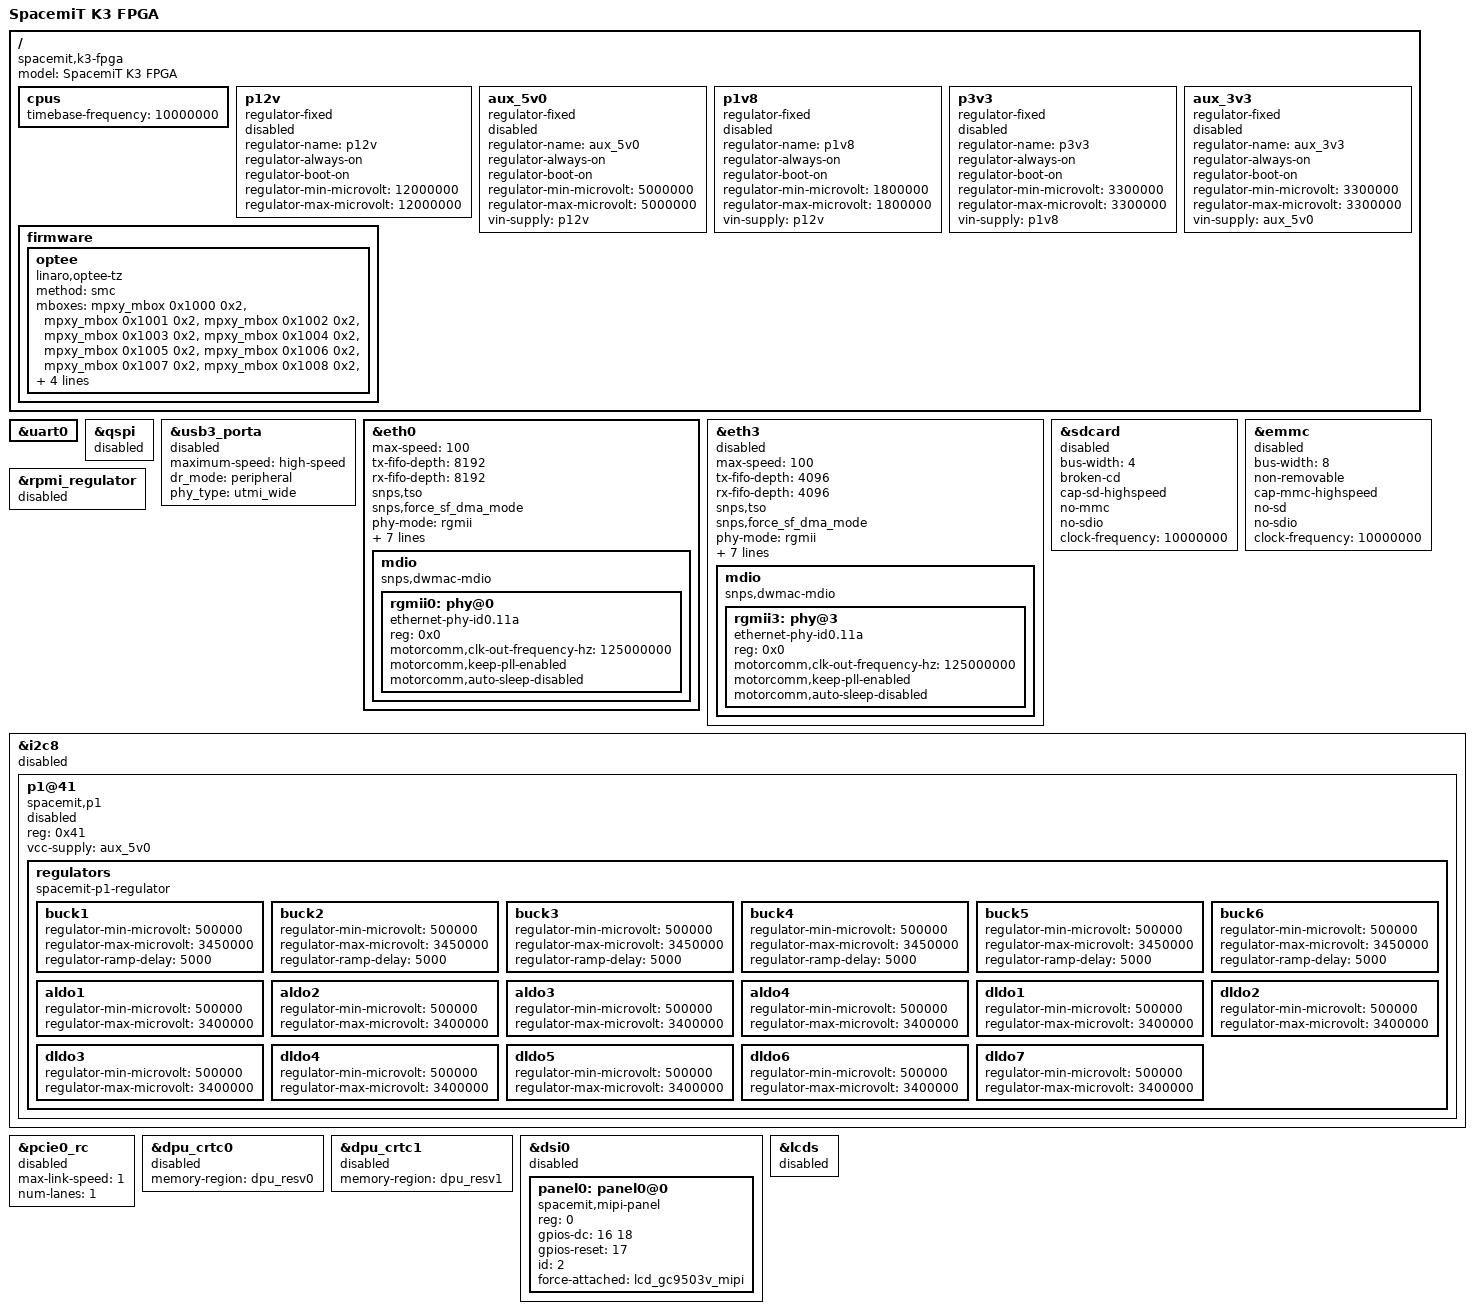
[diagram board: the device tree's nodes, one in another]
// SPDX-License-Identifier: (GPL-2.0 OR MIT)
/* Copyright (c) 2025 Spacemit, Inc */

#include "k3.dtsi"
#include "k3-rdomain.dtsi"
#include "lcd_dsi_panel.dtsi"
#include "lcd/lcd_gc9503v_mipi.dtsi"
#include "k3-camera.dtsi"
#include "k3-camera-sensor-fpga.dtsi"

/ {
	model = "SpacemiT K3 FPGA";
	compatible = "spacemit,k3-fpga";
	cpus: cpus {
		#address-cells = <1>;
		#size-cells = <0>;
		timebase-frequency = <10000000>;
	};

	p12v: p12v {
		compatible = "regulator-fixed";
		regulator-name = "p12v";
		regulator-always-on;
		regulator-boot-on;
		regulator-min-microvolt = <12000000>;
		regulator-max-microvolt = <12000000>;
		status = "disabled";
	};

	aux_5v0: aux_5v0 {
		compatible = "regulator-fixed";
		regulator-name = "aux_5v0";
		regulator-always-on;
		regulator-boot-on;
		regulator-min-microvolt = <5000000>;
		regulator-max-microvolt = <5000000>;
		vin-supply = <&p12v>;
		status = "disabled";
	};

	p1v8: p1v8 {
		compatible = "regulator-fixed";
		regulator-name = "p1v8";
		regulator-always-on;
		regulator-boot-on;
		regulator-min-microvolt = <1800000>;
		regulator-max-microvolt = <1800000>;
		vin-supply = <&p12v>;
		status = "disabled";
	};

	p3v3: p3v3 {
		compatible = "regulator-fixed";
		regulator-name = "p3v3";
		regulator-always-on;
		regulator-boot-on;
		regulator-min-microvolt = <3300000>;
		regulator-max-microvolt = <3300000>;
		vin-supply = <&p1v8>;
		status = "disabled";
	};

	aux_3v3: aux_3v3 {
		compatible = "regulator-fixed";
		regulator-name = "aux_3v3";
		regulator-always-on;
		regulator-boot-on;
		regulator-min-microvolt = <3300000>;
		regulator-max-microvolt = <3300000>;
		vin-supply = <&aux_5v0>;
		status = "disabled";
	};

	firmware {
		optee {
			compatible = "linaro,optee-tz";
			method = "smc";
			mboxes = <&mpxy_mbox 0x1000 0x2>,
				<&mpxy_mbox 0x1001 0x2>,
				<&mpxy_mbox 0x1002 0x2>,
				<&mpxy_mbox 0x1003 0x2>,
				<&mpxy_mbox 0x1004 0x2>,
				<&mpxy_mbox 0x1005 0x2>,
				<&mpxy_mbox 0x1006 0x2>,
				<&mpxy_mbox 0x1007 0x2>,
				<&mpxy_mbox 0x1008 0x2>,
				<&mpxy_mbox 0x1009 0x2>,
				<&mpxy_mbox 0x100a 0x2>,
				<&mpxy_mbox 0x100b 0x2>,
				<&mpxy_mbox 0x100c 0x2>,
				<&mpxy_mbox 0x100d 0x2>,
				<&mpxy_mbox 0x100e 0x2>,
				<&mpxy_mbox 0x100f 0x2>;
		};
	};
};

&uart0 {
	status = "okay";
};

&qspi {
	status = "disabled";
};

&usb3_porta {
	status = "disabled";
	maximum-speed = "high-speed";
	dr_mode = "peripheral";
	/delete-property/ phy_type;
	phy_type = "utmi_wide";
};

&eth0 {
	max-speed = <100>;
	tx-fifo-depth = <8192>;
	rx-fifo-depth = <8192>;
	snps,tso;
	snps,force_sf_dma_mode;
	phy-mode = "rgmii";
	phy-handle = <&rgmii0>;
	snps,reset-gpios = <&gpio 1 8 GPIO_ACTIVE_LOW>;

	spacemit,wake-irq-enable;
	spacemit,clk-tuning-enable;
	spacemit,clk-tuning-by-reg;
	spacemit,tx-phase = <0>;
	spacemit,rx-phase = <0>;

	status = "okay";

	mdio {
		#address-cells = <1>;
		#size-cells = <0>;
		compatible = "snps,dwmac-mdio";

		rgmii0: phy@0 {
			compatible = "ethernet-phy-id0.11a", "ethernet-phy-ieee802.3-c22";
			reg = <0x0>;

			motorcomm,clk-out-frequency-hz = <125000000>;
			motorcomm,keep-pll-enabled;
			motorcomm,auto-sleep-disabled;
		};
	};
};

&eth3 {
	max-speed = <100>;
	tx-fifo-depth = <4096>;
	rx-fifo-depth = <4096>;
	snps,tso;
	snps,force_sf_dma_mode;
	phy-mode = "rgmii";
	phy-handle = <&rgmii3>;
	snps,reset-gpios = <&gpio 2 16 GPIO_ACTIVE_LOW>;

	spacemit,wake-irq-enable;
	spacemit,clk-tuning-enable;
	spacemit,clk-tuning-by-reg;
	spacemit,tx-phase = <0>;
	spacemit,rx-phase = <0>;

	status = "disabled";

	mdio {
		#address-cells = <1>;
		#size-cells = <0>;
		compatible = "snps,dwmac-mdio";

		rgmii3: phy@3 {
			compatible = "ethernet-phy-id0.11a", "ethernet-phy-ieee802.3-c22";
			reg = <0x0>;

			motorcomm,clk-out-frequency-hz = <125000000>;
			motorcomm,keep-pll-enabled;
			motorcomm,auto-sleep-disabled;
		};
	};
};

&sdcard {
	bus-width = <4>;
	broken-cd;
	cap-sd-highspeed;
	no-mmc;
	no-sdio;
	clock-frequency = <10000000>;
	status = "disabled";
};

&emmc {
	bus-width = <8>;
	non-removable;
	cap-mmc-highspeed;
	no-sd;
	no-sdio;
	clock-frequency = <10000000>;
	status = "disabled";
};

&rpmi_regulator {
	status = "disabled";
/*
	pvin: pvin {
		regulator-min-microvolt = <5000000>;
		regulator-max-microvolt = <5000000>;
	};

	edcdc2: edcdc2 {
		regulator-min-microvolt = <800000>;
		regulator-max-microvolt = <800000>;
	};

	edcdc1: edcdc1 {
		regulator-min-microvolt = <500000>;
		regulator-max-microvolt = <3450000>;
	};

	p3v3: p3v3 {
		regulator-min-microvolt = <3300000>;
		regulator-max-microvolt = <3300000>;
	};

	p1v8: p1v8 {
		regulator-min-microvolt = <3300000>;
		regulator-max-microvolt = <3300000>;
	};

	dcdc1: dcdc1 {
		regulator-min-microvolt = <500000>;
		regulator-max-microvolt = <3450000>;
	};

	dcdc3: dcdc3 {
                regulator-min-microvolt = <500000>;
                regulator-max-microvolt = <1800000>;
	};

	dcdc4: dcdc4 {
                regulator-min-microvolt = <500000>;
                regulator-max-microvolt = <3300000>;
	};

	dcdc5: dcdc5 {
                regulator-min-microvolt = <500000>;
                regulator-max-microvolt = <3450000>;
	};

	dcdc6: dcdc6 {
                regulator-min-microvolt = <500000>;
                regulator-max-microvolt = <3450000>;
	};

	aldo1: aldo1 {
                regulator-min-microvolt = <500000>;
                regulator-max-microvolt = <3400000>;
	};

	aldo2: aldo2 {
                regulator-min-microvolt = <500000>;
                regulator-max-microvolt = <3400000>;
	};

	aldo3: aldo3 {
                regulator-min-microvolt = <500000>;
                regulator-max-microvolt = <3400000>;
	};

	aldo4: aldo4 {
                regulator-min-microvolt = <500000>;
                regulator-max-microvolt = <3400000>;
	};

	dldo1: dldo1 {
                regulator-min-microvolt = <500000>;
                regulator-max-microvolt = <3400000>;
	};

	dldo2: dldo2 {
                regulator-min-microvolt = <500000>;
                regulator-max-microvolt = <3400000>;
	};

	dldo3: dldo3 {
                regulator-min-microvolt = <500000>;
                regulator-max-microvolt = <3400000>;
	};

	dldo4: dldo4 {
                regulator-min-microvolt = <500000>;
                regulator-max-microvolt = <3400000>;
	};

	dldo5: dldo5 {
                regulator-min-microvolt = <500000>;
                regulator-max-microvolt = <3400000>;
	};

	dldo6: dldo6 {
                regulator-min-microvolt = <500000>;
                regulator-max-microvolt = <3400000>;
	};

	dldo7: dldo7 {
                regulator-min-microvolt = <500000>;
                regulator-max-microvolt = <3400000>;
	};

	pwr_x100: pwr_x100 {
		regulator-min-microvolt = <3300000>;
		regulator-max-microvolt = <3300000>;
	};

	pwr_a100: pwr_a100 {
		regulator-min-microvolt = <3300000>;
		regulator-max-microvolt = <3300000>;
	};

	pwr_ext: pwr_ext {
		regulator-min-microvolt = <3300000>;
		regulator-max-microvolt = <3300000>;
	};
*/
};

&i2c8 {
	/* pinctrl-names = "default"; */
	/* pinctrl-0 = <&pinctrl_i2c8>; */
	status = "disabled";

	p1@41 {
		compatible = "spacemit,p1";
		reg = <0x41>;
		status = "disabled";

		vcc-supply = <&aux_5v0>;

		regulators {
			compatible = "spacemit-p1-regulator";

			/* buck */
			buck1: buck1 {
				regulator-min-microvolt = <500000>;
				regulator-max-microvolt = <3450000>;
				regulator-ramp-delay = <5000>;
			};

			buck2: buck2 {
				regulator-min-microvolt = <500000>;
				regulator-max-microvolt = <3450000>;
				regulator-ramp-delay = <5000>;
			};

			buck3: buck3 {
				regulator-min-microvolt = <500000>;
				regulator-max-microvolt = <3450000>;
				regulator-ramp-delay = <5000>;
			};

			buck4: buck4 {
				regulator-min-microvolt = <500000>;
				regulator-max-microvolt = <3450000>;
				regulator-ramp-delay = <5000>;
			};

			buck5: buck5 {
				regulator-min-microvolt = <500000>;
				regulator-max-microvolt = <3450000>;
				regulator-ramp-delay = <5000>;
			};

			buck6: buck6 {
				regulator-min-microvolt = <500000>;
				regulator-max-microvolt = <3450000>;
				regulator-ramp-delay = <5000>;
			};

			/* aldo */
			aldo1: aldo1 {
				regulator-min-microvolt = <500000>;
				regulator-max-microvolt = <3400000>;
			};

			aldo2: aldo2 {
				regulator-min-microvolt = <500000>;
				regulator-max-microvolt = <3400000>;
			};

			aldo3: aldo3 {
				regulator-min-microvolt = <500000>;
				regulator-max-microvolt = <3400000>;
			};

			aldo4: aldo4 {
				regulator-min-microvolt = <500000>;
				regulator-max-microvolt = <3400000>;
			};

			/* dldo */
			dldo1: dldo1 {
				regulator-min-microvolt = <500000>;
				regulator-max-microvolt = <3400000>;
			};

			dldo2: dldo2 {
				regulator-min-microvolt = <500000>;
				regulator-max-microvolt = <3400000>;
			};

			dldo3: dldo3 {
				regulator-min-microvolt = <500000>;
				regulator-max-microvolt = <3400000>;
			};

			dldo4: dldo4 {
				regulator-min-microvolt = <500000>;
				regulator-max-microvolt = <3400000>;
			};

			dldo5: dldo5 {
				regulator-min-microvolt = <500000>;
				regulator-max-microvolt = <3400000>;
			};

			dldo6: dldo6 {
				regulator-min-microvolt = <500000>;
				regulator-max-microvolt = <3400000>;
			};

			dldo7: dldo7 {
				regulator-min-microvolt = <500000>;
				regulator-max-microvolt = <3400000>;
			};
		};
	};
};

&pcie0_rc {
	max-link-speed = <1>;
	num-lanes = <1>;
	status = "disabled";
};


&dpu_crtc0 {
	memory-region = <&dpu_resv0>;
	status = "disabled";
};

&dpu_crtc1 {
	memory-region = <&dpu_resv1>;
	status = "disabled";
};

&dsi0 {
	status = "disabled";

	panel0: panel0@0 {
		status = "ok";
		compatible = "spacemit,mipi-panel";
		reg = <0>;
		gpios-dc = <16 18>;
		gpios-reset = <17>;
		id = <2>;
		force-attached = "lcd_gc9503v_mipi";
	};
};

&lcds {
	status = "disabled";
};
